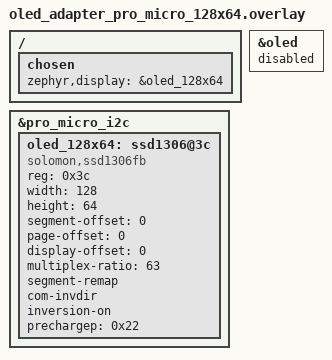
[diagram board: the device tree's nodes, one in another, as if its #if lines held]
/*
 * Copyright (c) 2025 The ZMK Contributors
 *
 * SPDX-License-Identifier: MIT
 */

/*
 * 1. checks if the label "oled" was defined on the shields/boards and if so
 *    disables it. It is a simple but better implementation than
 *    "/delete-node/ &oled;" because it adds oled_xxx from scratch, that is,
 *    even "if the node oled" did not exist before
 * 2. Macros like #if defined(DT_NODELABEL_oled) do not require any #include in
 * the .overlay or .dts files. the build system automatically defines them in
 * the preprocessor before compiling the devicetree.
 * 3. ref1: https://docs.zephyrproject.org/apidoc/latest/group__devicetree-generic-id.html
 * 4. ref2: nvim zmk/zephyr/include/zephyr/devicetree.h
 * test:
 *       grep -n "zephyr,display" zmk/build/zephyr/zephyr.dts
 *       zephyr,display = &oled_128x128;
 */

// /delete-node/ &oled;
#if defined(DT_NODELABEL_oled)
&oled {
    status = "disabled";
};
#endif

&pro_micro_i2c {
    status = "okay";

    oled_128x64: ssd1306@3c {
        compatible = "solomon,ssd1306fb";
        reg = <0x3c>;
        width = <128>;
        height = <64>;
        segment-offset = <0>;
        page-offset = <0>;
        display-offset = <0>;
        multiplex-ratio = <63>;
        segment-remap;
        com-invdir;
        inversion-on;
        prechargep = <0x22>;
    };
};

/ {
    chosen {
        zephyr,display = &oled_128x64;
    };
};
// vim: filetype=dts fdm=marker:
